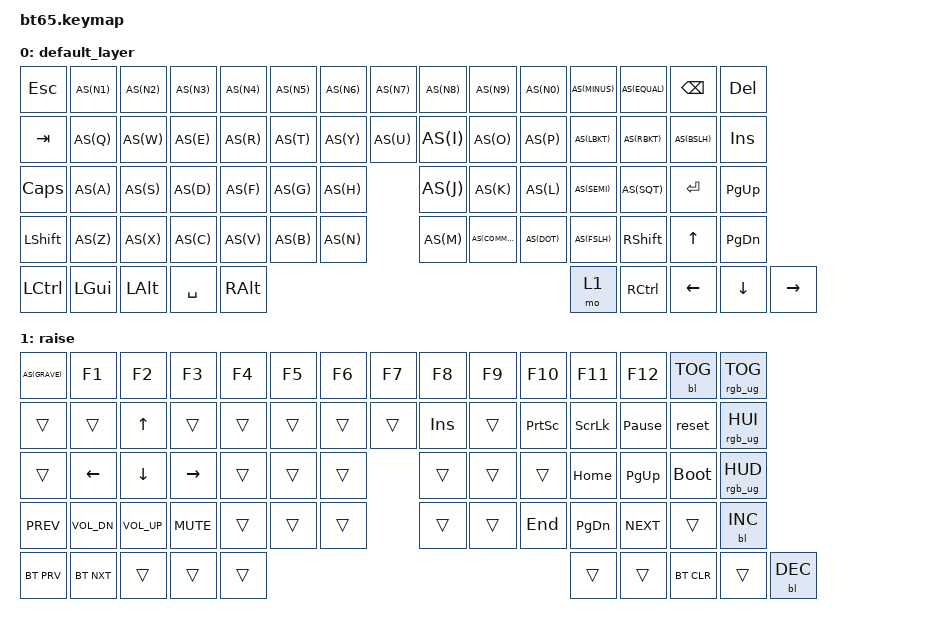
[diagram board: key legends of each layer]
#include <behaviors.dtsi>
#include <dt-bindings/zmk/keys.h>
#include <dt-bindings/zmk/bt.h>
#include <dt-bindings/zmk/rgb.h>
#include <dt-bindings/zmk/backlight.h>
#include <dt-bindings/zmk/ext_power.h>
// #include <dt-bindings/zmk/mouse.h>
// &mmv MOVE_UP

#define AS(keycode) &as LS(keycode) keycode     // Autoshift Macro
/ {
	behaviors {
		as: auto_shift {
			compatible = "zmk,behavior-hold-tap";
			label = "AUTO_SHIFT";
			#binding-cells = <2>;
			tapping_term_ms = <175>;
			quick_tap_ms = <0>;
			flavor = "tap-preferred";
			bindings = <&kp>, <&kp>;
		};
	};
	keymap {
		compatible = "zmk,keymap";

		default_layer {
				// ------------------------------------------------------------------------------------------------------------
				// |  `  |  1  |  2  |  3  |  4  |  5  |  6  |  7  |  8  |  9  |  0  |  -  |  =  |BKSP | INS		|
				// | TAB  |  Q  |  W  |  E  |  R  |  T  |  Y  |  U  |  I  |  O  |  P  |  [  |  ]  |   \    | DEL		|
				// | CAPS  |  A  |  S  |  D  |  F  |  G  |  H  |  J  |  K  |  L  |  ;  |  '  |     ENTER    |PGUP	|
				// |  SHIFT  |  Z  |  X  |  C  |  V  |  B  |  N  |  M  |  ,  |  .  | /   |   SHIFT  | UP   | PGDN|
				// |  CTL  |  WIN  |  ALT  |            SPACE               | ALT | 1    |  MENU| LEFT |  DOWN    | RIGHT	|
				// ------------------------------------------------------------------------------------------------------------
			bindings = <
				&kp ESC  AS(N1) AS(N2) AS(N3) AS(N4) AS(N5) AS(N6) AS(N7) AS(N8) AS(N9) AS(N0) AS(MINUS) AS(EQUAL)  &kp BKSP &kp DEL
				&kp TAB  AS(Q)  AS(W)  AS(E)  AS(R)  AS(T)  AS(Y)  AS(U)  AS(I)  AS(O)  AS(P)  AS(LBKT)  AS(RBKT)   AS(BSLH) &kp INS
				&kp CLCK AS(A)  AS(S)  AS(D)  AS(F)  AS(G)  AS(H)  AS(J)  AS(K)  AS(L)  AS(SEMI) AS(SQT)            &kp RET  &kp PG_UP
				&kp LSHFT AS(Z) AS(X)  AS(C)  AS(V)  AS(B)  AS(N)  AS(M)  AS(COMMA) AS(DOT) AS(FSLH)  &kp RSHFT	    &kp UP &kp PG_DN
				&kp LCTRL &kp LGUI &kp LALT            &kp SPACE                          &kp RALT  &mo 1 &kp RCTRL &kp LEFT &kp DOWN &kp RIGHT
			>;
			sensor-bindings = <&inc_dec_kp C_VOL_UP C_VOL_DN>;
		};
		raise {
			bindings = <
				AS(GRAVE) &kp F1 &kp F2 &kp F3 &kp F4 &kp F5 &kp F6 &kp F7 &kp  F8   &kp  F9   &kp F10  &kp F11 &kp F12 &bl BL_TOG &rgb_ug RGB_TOG
				&trans &trans &kp UP &trans &trans &trans &trans &trans &kp INS &trans &kp PSCRN &kp SLCK &kp PAUSE_BREAK &reset &rgb_ug RGB_HUI
				&trans    &kp LEFT &kp DOWN &kp RIGHT &trans &trans &trans &trans &trans &trans &kp HOME  &kp PG_UP   &bootloader &rgb_ug RGB_HUD
				&kp C_PREV &kp C_VOL_DN &kp C_VOL_UP &kp C_MUTE &trans &trans &trans &trans &trans &kp END &kp PG_DN  &kp C_NEXT &trans &bl BL_INC
				&bt BT_PRV &bt BT_NXT  &trans              &trans                            &trans   &trans   &trans &bt BT_CLR &trans &bl BL_DEC
			>;
			sensor-bindings = <&inc_dec_kp C_VOL_UP C_VOL_DN>;
		};
	};
};
